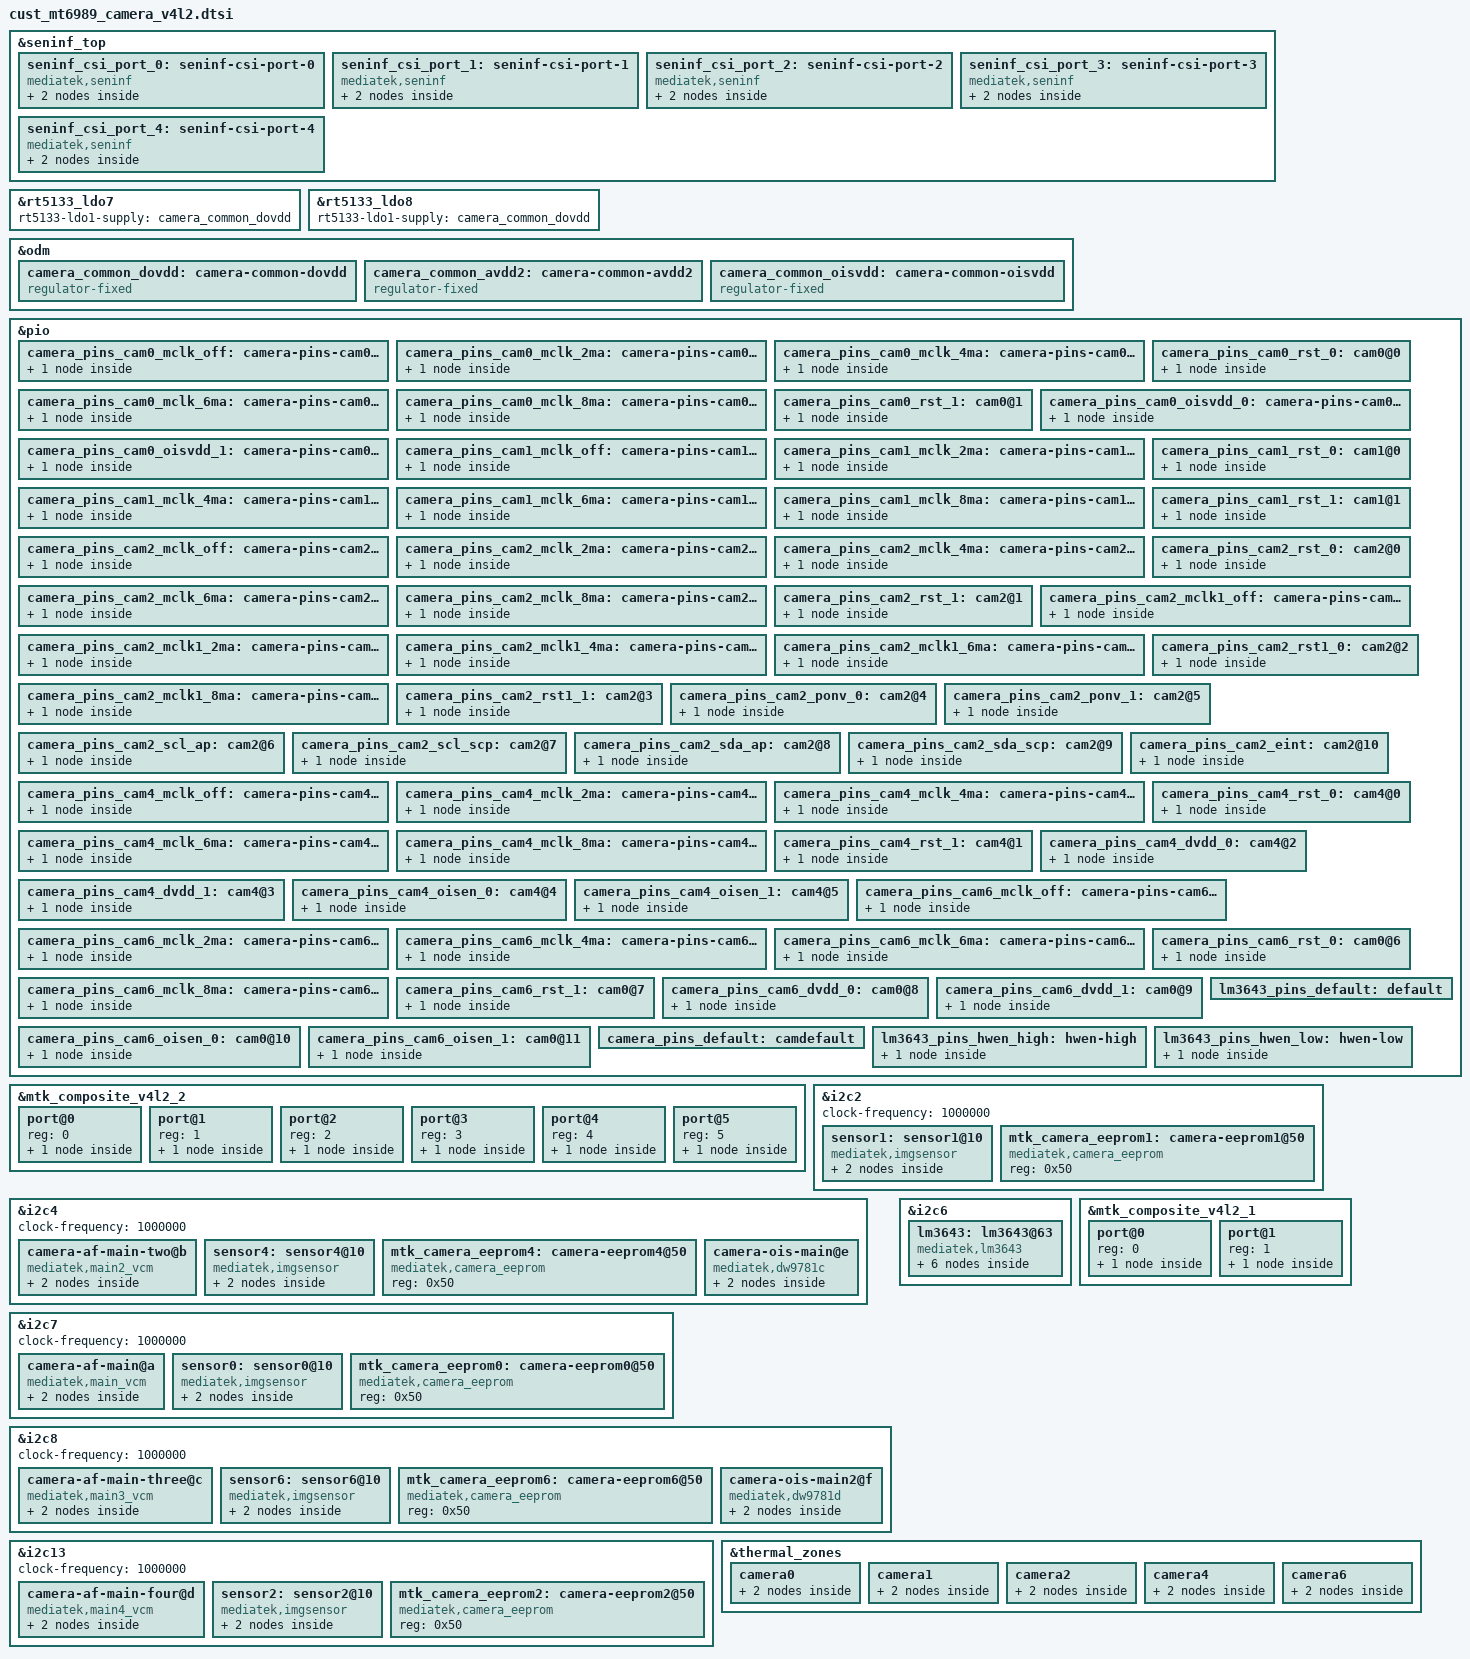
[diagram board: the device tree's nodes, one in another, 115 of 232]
// SPDX-License-Identifier: GPL-2.0
/* Copyright (c) 2023 MediaTek Inc. */
#include <dt-bindings/clock/mt6989-clk.h>

&seninf_top {
		seninf_csi_port_0: seninf-csi-port-0 {
			compatible = "mediatek,seninf";
			csi-port = "0";

			nvmem-cells = <&csi_efuse0>;
			nvmem-cell-names = "rg_csi";

			port {
				seninf_csi_port_0_in: endpoint {
					remote-endpoint = <&sensor1_out>;
				};
			};
		};

		seninf_csi_port_1: seninf-csi-port-1 {
			compatible = "mediatek,seninf";
			csi-port = "1";

			nvmem-cells = <&csi_efuse1>;
			nvmem-cell-names = "rg_csi";

			port {
				seninf_csi_port_1_in: endpoint {
					remote-endpoint = <&sensor6_out>;
				};
			};
		};

		seninf_csi_port_2: seninf-csi-port-2 {
			compatible = "mediatek,seninf";
			csi-port = "2";

			nvmem-cells = <&csi_efuse2>;
			nvmem-cell-names = "rg_csi";

			port {
				seninf_csi_port_2_in: endpoint {
					remote-endpoint = <&sensor4_out>;
				};
			};
		};
		seninf_csi_port_3: seninf-csi-port-3 {
			compatible = "mediatek,seninf";
			csi-port = "3";

			nvmem-cells = <&csi_efuse3>;
			nvmem-cell-names = "rg_csi";

			port {
				seninf_csi_port_3_in: endpoint {
					remote-endpoint = <&sensor0_out>;
				};
			};
		};
		seninf_csi_port_4: seninf-csi-port-4 {
			compatible = "mediatek,seninf";
			csi-port = "4";

			nvmem-cells = <&csi_efuse4>;
			nvmem-cell-names = "rg_csi";

			port {
				seninf_csi_port_4_in: endpoint {
					remote-endpoint = <&sensor2_out>;
				};
			};
		};
};

&rt5133_ldo7 {
	rt5133-ldo1-supply = <&camera_common_dovdd>;
};

&rt5133_ldo8 {
	rt5133-ldo1-supply = <&camera_common_dovdd>;
};

/* CAMERA GPIO fixed to regulator */
&odm {
	camera_common_dovdd: camera-common-dovdd {
		compatible = "regulator-fixed";
		regulator-name = "camera-common-dovdd";
		regulator-min-microvolt = <1800000>;
		regulator-max-microvolt = <1800000>;
		enable-active-high;
		gpio = <&pio 92 0x0>;
	};
	camera_common_avdd2: camera-common-avdd2 {
		compatible = "regulator-fixed";
		regulator-name = "camera-common-avdd2";
		regulator-min-microvolt = <1800000>;
		regulator-max-microvolt = <1800000>;
		enable-active-high;
		gpio = <&pio 93 0x0>;
	};
	camera_common_oisvdd: camera-common-oisvdd {
		compatible = "regulator-fixed";
		regulator-name = "camera-common-oisvdd";
		regulator-min-microvolt = <1800000>;
		regulator-max-microvolt = <1800000>;
		enable-active-high;
		gpio = <&pio 94 0x0>;
	};
};

/* CAMERA GPIO standardization */
&pio {
	camera_pins_cam0_mclk_off: camera-pins-cam0-mclk-off {
		pins-cmd-dat {
			pinmux = <PINMUX_GPIO116__FUNC_GPIO116>;
			drive-strength = <1>;
		};
	};
	camera_pins_cam0_mclk_2ma: camera-pins-cam0-mclk-2ma {
		pins-cmd-dat {
			pinmux = <PINMUX_GPIO116__FUNC_CMMCLK2>;
			drive-strength = <0>;
		};
	};
	camera_pins_cam0_mclk_4ma: camera-pins-cam0-mclk-4ma {
		pins-cmd-dat {
			pinmux = <PINMUX_GPIO116__FUNC_CMMCLK2>;
			drive-strength = <1>;
		};
	};
	camera_pins_cam0_mclk_6ma: camera-pins-cam0-mclk-6ma {
		pins-cmd-dat {
			pinmux = <PINMUX_GPIO116__FUNC_CMMCLK2>;
			drive-strength = <2>;
		};
	};
	camera_pins_cam0_mclk_8ma: camera-pins-cam0-mclk-8ma {
		pins-cmd-dat {
			pinmux = <PINMUX_GPIO116__FUNC_CMMCLK2>;
			drive-strength = <3>;
		};
	};
	camera_pins_cam0_rst_0: cam0@0 {
		pins-cmd-dat {
			pinmux = <PINMUX_GPIO118__FUNC_GPIO118>;
			slew-rate = <1>;
			output-low;
		};
	};
	camera_pins_cam0_rst_1: cam0@1 {
		pins-cmd-dat {
			pinmux = <PINMUX_GPIO118__FUNC_GPIO118>;
			slew-rate = <1>;
			output-high;
		};
	};
	camera_pins_cam0_oisvdd_0: camera-pins-cam0-oisvdd-0 {
		pins-cmd-dat {
			pinmux = <PINMUX_GPIO95__FUNC_GPIO95>;
			slew-rate = <1>;
			output-low;
		};
	};
	camera_pins_cam0_oisvdd_1: camera-pins-cam0-oisvdd-1 {
		pins-cmd-dat {
			pinmux = <PINMUX_GPIO95__FUNC_GPIO95>;
			slew-rate = <1>;
			output-high;
		};
	};
	camera_pins_cam1_mclk_off: camera-pins-cam1-mclk-off {
		pins-cmd-dat {
			pinmux = <PINMUX_GPIO106__FUNC_GPIO106>;
			drive-strength = <1>;
		};
	};
	camera_pins_cam1_mclk_2ma: camera-pins-cam1-mclk-2ma {
		pins-cmd-dat {
			pinmux = <PINMUX_GPIO106__FUNC_CMMCLK4>;
			drive-strength = <0>;
		};
	};
	camera_pins_cam1_mclk_4ma: camera-pins-cam1-mclk-4ma {
		pins-cmd-dat {
			pinmux = <PINMUX_GPIO106__FUNC_CMMCLK4>;
			drive-strength = <1>;
		};
	};
	camera_pins_cam1_mclk_6ma: camera-pins-cam1-mclk-6ma {
		pins-cmd-dat {
			pinmux = <PINMUX_GPIO106__FUNC_CMMCLK4>;
			drive-strength = <2>;
		};
	};
	camera_pins_cam1_mclk_8ma: camera-pins-cam1-mclk-8ma {
		pins-cmd-dat {
			pinmux = <PINMUX_GPIO106__FUNC_CMMCLK4>;
			drive-strength = <3>;
		};
	};
	camera_pins_cam1_rst_0: cam1@0 {
		pins-cmd-dat {
			pinmux = <PINMUX_GPIO114__FUNC_GPIO114>;
			slew-rate = <1>;
			output-low;
		};
	};
	camera_pins_cam1_rst_1: cam1@1 {
		pins-cmd-dat {
			pinmux = <PINMUX_GPIO114__FUNC_GPIO114>;
			slew-rate = <1>;
			output-high;
		};
	};
	camera_pins_cam2_mclk_off: camera-pins-cam2-mclk-off {
		pins-cmd-dat {
			pinmux = <PINMUX_GPIO117__FUNC_GPIO117>;
			drive-strength = <1>;
		};
	};
	camera_pins_cam2_mclk_2ma: camera-pins-cam2-mclk-2ma {
		pins-cmd-dat {
			pinmux = <PINMUX_GPIO117__FUNC_CMMCLK3>;
			drive-strength = <0>;
		};
	};
	camera_pins_cam2_mclk_4ma: camera-pins-cam2-mclk-4ma {
		pins-cmd-dat {
			pinmux = <PINMUX_GPIO117__FUNC_CMMCLK3>;
			drive-strength = <1>;
		};
	};
	camera_pins_cam2_mclk_6ma: camera-pins-cam2-mclk-6ma {
		pins-cmd-dat {
			pinmux = <PINMUX_GPIO117__FUNC_CMMCLK3>;
			drive-strength = <2>;
		};
	};
	camera_pins_cam2_mclk_8ma: camera-pins-cam2-mclk-8ma {
		pins-cmd-dat {
			pinmux = <PINMUX_GPIO117__FUNC_CMMCLK3>;
			drive-strength = <3>;
		};
	};
	camera_pins_cam2_rst_0: cam2@0 {
		pins-cmd-dat {
			pinmux = <PINMUX_GPIO119__FUNC_GPIO119>;
			slew-rate = <1>;
			output-low;
		};
	};
	camera_pins_cam2_rst_1: cam2@1 {
		pins-cmd-dat {
			pinmux = <PINMUX_GPIO119__FUNC_GPIO119>;
			slew-rate = <1>;
			output-high;
		};
	};
	camera_pins_cam2_mclk1_off: camera-pins-cam2-mclk1-off {
		pins-cmd-dat {
			pinmux = <PINMUX_GPIO124__FUNC_GPIO124>;
			drive-strength = <1>;
		};
	};
	camera_pins_cam2_mclk1_2ma: camera-pins-cam2-mclk1-2ma {
		pins-cmd-dat {
			pinmux = <PINMUX_GPIO124__FUNC_CMMCLK0>;
			drive-strength = <0>;
		};
	};
	camera_pins_cam2_mclk1_4ma: camera-pins-cam2-mclk1-4ma {
		pins-cmd-dat {
			pinmux = <PINMUX_GPIO124__FUNC_CMMCLK0>;
			drive-strength = <1>;
		};
	};
	camera_pins_cam2_mclk1_6ma: camera-pins-cam2-mclk1-6ma {
		pins-cmd-dat {
			pinmux = <PINMUX_GPIO124__FUNC_CMMCLK0>;
			drive-strength = <2>;
		};
	};
	camera_pins_cam2_mclk1_8ma: camera-pins-cam2-mclk1-8ma {
		pins-cmd-dat {
			pinmux = <PINMUX_GPIO124__FUNC_CMMCLK0>;
			drive-strength = <3>;
		};
	};
	camera_pins_cam2_rst1_0: cam2@2 {
		pins-cmd-dat {
			pinmux = <PINMUX_GPIO160__FUNC_GPIO160>;
			slew-rate = <1>;
			output-low;
		};
	};
	camera_pins_cam2_rst1_1: cam2@3 {
		pins-cmd-dat {
			pinmux = <PINMUX_GPIO160__FUNC_GPIO160>;
			slew-rate = <1>;
			output-high;
		};
	};
	camera_pins_cam2_ponv_0: cam2@4 {
		pins-cmd-dat {
			pinmux = <PINMUX_GPIO159__FUNC_GPIO159>;
			slew-rate = <1>;
			output-low;
		};
	};
	camera_pins_cam2_ponv_1: cam2@5 {
		pins-cmd-dat {
			pinmux = <PINMUX_GPIO159__FUNC_GPIO159>;
			slew-rate = <1>;
			output-high;
		};
	};
	camera_pins_cam2_scl_ap: cam2@6 {
		pins-cmd-dat {
			pinmux = <PINMUX_GPIO104__FUNC_SCL13>;
		};
	};
	camera_pins_cam2_scl_scp: cam2@7 {
		pins-cmd-dat {
			pinmux = <PINMUX_GPIO104__FUNC_SCP_SCL3>;
		};
	};
	camera_pins_cam2_sda_ap: cam2@8 {
		pins-cmd-dat {
			pinmux = <PINMUX_GPIO105__FUNC_SDA13>;
		};
	};
	camera_pins_cam2_sda_scp: cam2@9 {
		pins-cmd-dat {
			pinmux = <PINMUX_GPIO105__FUNC_SCP_SDA3>;
		};
	};
	camera_pins_cam2_eint: cam2@10 {
		pins-cmd-dat {
			pinmux = <PINMUX_GPIO109__FUNC_GPIO109>;
			bias-pull-up;
			input-enable;
		};
	};
	camera_pins_cam4_mclk_off: camera-pins-cam4-mclk-off {
		pins-cmd-dat {
			pinmux = <PINMUX_GPIO125__FUNC_GPIO125>;
			drive-strength = <1>;
		};
	};
	camera_pins_cam4_mclk_2ma: camera-pins-cam4-mclk-2ma {
		pins-cmd-dat {
			pinmux = <PINMUX_GPIO125__FUNC_CMMCLK1>;
			drive-strength = <0>;
		};
	};
	camera_pins_cam4_mclk_4ma: camera-pins-cam4-mclk-4ma {
		pins-cmd-dat {
			pinmux = <PINMUX_GPIO125__FUNC_CMMCLK1>;
			drive-strength = <1>;
		};
	};
	camera_pins_cam4_mclk_6ma: camera-pins-cam4-mclk-6ma {
		pins-cmd-dat {
			pinmux = <PINMUX_GPIO125__FUNC_CMMCLK1>;
			drive-strength = <2>;
		};
	};
	camera_pins_cam4_mclk_8ma: camera-pins-cam4-mclk-8ma {
		pins-cmd-dat {
			pinmux = <PINMUX_GPIO125__FUNC_CMMCLK1>;
			drive-strength = <3>;
		};
	};
	camera_pins_cam4_rst_0: cam4@0 {
		pins-cmd-dat {
			pinmux = <PINMUX_GPIO127__FUNC_GPIO127>;
			slew-rate = <1>;
			output-low;
		};
	};
	camera_pins_cam4_rst_1: cam4@1 {
		pins-cmd-dat {
			pinmux = <PINMUX_GPIO127__FUNC_GPIO127>;
			slew-rate = <1>;
			output-high;
		};
	};
	camera_pins_cam4_dvdd_0: cam4@2 {
		pins-cmd-dat {
			pinmux = <PINMUX_GPIO108__FUNC_GPIO108>;
			slew-rate = <1>;
			output-low;
		};
	};
	camera_pins_cam4_dvdd_1: cam4@3 {
		pins-cmd-dat {
			pinmux = <PINMUX_GPIO108__FUNC_GPIO108>;
			slew-rate = <1>;
			output-high;
		};
	};
	camera_pins_cam4_oisen_0: cam4@4 {
		pins-cmd-dat {
			pinmux = <PINMUX_GPIO189__FUNC_GPIO189>;
			slew-rate = <1>;
			output-low;
		};
	};
	camera_pins_cam4_oisen_1: cam4@5 {
		pins-cmd-dat {
			pinmux = <PINMUX_GPIO189__FUNC_GPIO189>;
			slew-rate = <1>;
			output-high;
		};
	};
	camera_pins_cam6_mclk_off: camera-pins-cam6-mclk-off {
		pins-cmd-dat {
			pinmux = <PINMUX_GPIO107__FUNC_GPIO107>;
			drive-strength = <1>;
		};
	};
	camera_pins_cam6_mclk_2ma: camera-pins-cam6-mclk-2ma {
		pins-cmd-dat {
			pinmux = <PINMUX_GPIO107__FUNC_CMMCLK5>;
			drive-strength = <0>;
		};
	};
	camera_pins_cam6_mclk_4ma: camera-pins-cam6-mclk-4ma {
		pins-cmd-dat {
			pinmux = <PINMUX_GPIO107__FUNC_CMMCLK5>;
			drive-strength = <1>;
		};
	};
	camera_pins_cam6_mclk_6ma: camera-pins-cam6-mclk-6ma {
		pins-cmd-dat {
			pinmux = <PINMUX_GPIO107__FUNC_CMMCLK5>;
			drive-strength = <2>;
		};
	};
	camera_pins_cam6_mclk_8ma: camera-pins-cam6-mclk-8ma {
		pins-cmd-dat {
			pinmux = <PINMUX_GPIO107__FUNC_CMMCLK5>;
			drive-strength = <3>;
		};
	};
	camera_pins_cam6_rst_0: cam0@6 {
		pins-cmd-dat {
			pinmux = <PINMUX_GPIO110__FUNC_GPIO110>;
			slew-rate = <1>;
			output-low;
		};
	};
	camera_pins_cam6_rst_1: cam0@7 {
		pins-cmd-dat {
			pinmux = <PINMUX_GPIO110__FUNC_GPIO110>;
			slew-rate = <1>;
			output-high;
		};
	};
	camera_pins_cam6_dvdd_0: cam0@8 {
		pins-cmd-dat {
			pinmux = <PINMUX_GPIO126__FUNC_GPIO126>;
			slew-rate = <1>;
			output-low;
		};
	};
	camera_pins_cam6_dvdd_1: cam0@9 {
		pins-cmd-dat {
			pinmux = <PINMUX_GPIO126__FUNC_GPIO126>;
			slew-rate = <1>;
			output-high;
		};
	};
	camera_pins_cam6_oisen_0: cam0@10 {
		pins-cmd-dat {
			pinmux = <PINMUX_GPIO223__FUNC_GPIO223>;
			slew-rate = <1>;
			output-low;
		};
	};
	camera_pins_cam6_oisen_1: cam0@11 {
		pins-cmd-dat {
			pinmux = <PINMUX_GPIO223__FUNC_GPIO223>;
			slew-rate = <1>;
			output-high;
		};
	};
	camera_pins_default: camdefault {
	};
};
/* CAMERA GPIO end */

&mtk_composite_v4l2_2 {
	#address-cells = <1>;
	#size-cells = <0>;
	port@0 {
		reg = <0>;
		main_af_endpoint: endpoint {
			remote-endpoint = <&main_af>;
		};
	};
	port@1 {
		reg = <1>;
		main_af_cam1_endpoint: endpoint {
			remote-endpoint = <&main_af_cam1>;
		};
	};
	port@2 {
		reg = <2>;
		main_af_cam2_endpoint: endpoint {
			remote-endpoint = <&main_af_cam2>;
		};
	};
	port@3 {
		reg = <3>;
		main_af_cam3_endpoint: endpoint {
			remote-endpoint = <&main_af_cam3>;
		};
	};
	port@4 {
		reg = <4>;
		main_ois_cam1_endpoint: endpoint {
			remote-endpoint = <&main_ois_cam1>;
		};
	};
	port@5 {
		reg = <5>;
		main_ois_cam2_endpoint: endpoint {
			remote-endpoint = <&main_ois_cam2>;
		};
	};
};

&i2c2 {
	status = "okay";
	clock-frequency = <1000000>;

	sensor1: sensor1@10 {
		compatible = "mediatek,imgsensor";
		sensor-names = "s5k3p9sp_mipi_raw";
		reg = <0x10>;

		#thermal-sensor-cells = <0>;

		pinctrl-names = "mclk_off",
				"mclk_2mA",
				"mclk_4mA",
				"mclk_6mA",
				"mclk_8mA",
				"rst_low",
				"rst_high";
		pinctrl-0 = <&camera_pins_cam1_mclk_off>;
		pinctrl-1 = <&camera_pins_cam1_mclk_2ma>;
		pinctrl-2 = <&camera_pins_cam1_mclk_4ma>;
		pinctrl-3 = <&camera_pins_cam1_mclk_6ma>;
		pinctrl-4 = <&camera_pins_cam1_mclk_8ma>;
		pinctrl-5 = <&camera_pins_cam1_rst_0>;
		pinctrl-6 = <&camera_pins_cam1_rst_1>;

		avdd-supply = <&rt5133_ldo3>;
		dvdd1-supply = <&rt5133_gpio3>;
		dovdd-supply = <&camera_common_dovdd>;

		clocks = <&topckgen_clk CLK_TOP_UNIVPLL2_192M_D32>,
			<&topckgen_clk CLK_TOP_UNIVPLL2_192M_D16>,
			<&topckgen_clk CLK_TOP_F26M_CK_D2>,
			<&topckgen_clk CLK_TOP_UNIVPLL2_192M_D10>,
			<&topckgen_clk CLK_TOP_UNIVPLL2_192M_D8>,
			<&topckgen_clk CLK_TOP_UNIVPLL2_D6_D16>,
			<&topckgen_clk CLK_TOP_UNIVPLL2_D6_D8>,
			<&topckgen_clk CLK_TOP_CAMTG4_SEL>;
		clock-names = "6", "12", "13", "19.2", "24", "26", "52", "mclk";

		status = "okay";
		port {
			sensor1_out: endpoint {
				remote-endpoint = <&seninf_csi_port_0_in>;
			};
		};
	};

	mtk_camera_eeprom1:camera-eeprom1@50 {
		compatible = "mediatek,camera_eeprom";
		reg = <0x50>;
		status = "okay";
	};
};

&i2c4 {
	status = "okay";
	clock-frequency = <1000000>;

	camera-af-main-two@b {
		compatible = "mediatek,main2_vcm";
		reg = <0x0b>;
		vin-supply = <&rt5133_ldo2>;
		port {
			main_af_cam1: endpoint {
				remote-endpoint = <&main_af_cam1_endpoint>;
			};
		};
	};

	sensor4: sensor4@10 {
		compatible = "mediatek,imgsensor";
		sensor-names = "imx758_mipi_raw";
		reg = <0x10>;

		#thermal-sensor-cells = <0>;

		pinctrl-names = "mclk_off",
				"mclk_2mA",
				"mclk_4mA",
				"mclk_6mA",
				"mclk_8mA",
				"rst_low",
				"rst_high",
				"dvdd_off",
				"dvdd_on",
				"oisen_off",
				"oisen_on";
		pinctrl-0 = <&camera_pins_cam4_mclk_off>;
		pinctrl-1 = <&camera_pins_cam4_mclk_2ma>;
		pinctrl-2 = <&camera_pins_cam4_mclk_4ma>;
		pinctrl-3 = <&camera_pins_cam4_mclk_6ma>;
		pinctrl-4 = <&camera_pins_cam4_mclk_8ma>;
		pinctrl-5 = <&camera_pins_cam4_rst_0>;
		pinctrl-6 = <&camera_pins_cam4_rst_1>;
		pinctrl-7 = <&camera_pins_cam4_dvdd_0>;
		pinctrl-8 = <&camera_pins_cam4_dvdd_1>;
		pinctrl-9 = <&camera_pins_cam4_oisen_0>;
		pinctrl-10 = <&camera_pins_cam4_oisen_1>;

		avdd-supply = <&rt5133_ldo3>;
		afvdd-supply = <&rt5133_ldo2>;
		dovdd-supply = <&camera_common_dovdd>;
		oisvdd-supply = <&rt5133_ldo1>;

		clocks = <&topckgen_clk CLK_TOP_UNIVPLL2_192M_D32>,
			<&topckgen_clk CLK_TOP_UNIVPLL2_192M_D16>,
			<&topckgen_clk CLK_TOP_F26M_CK_D2>,
			<&topckgen_clk CLK_TOP_UNIVPLL2_192M_D10>,
			<&topckgen_clk CLK_TOP_UNIVPLL2_192M_D8>,
			<&topckgen_clk CLK_TOP_UNIVPLL2_D6_D16>,
			<&topckgen_clk CLK_TOP_UNIVPLL2_D6_D8>,
			<&topckgen_clk CLK_TOP_CAMTG1_SEL>;
		clock-names = "6", "12", "13", "19.2", "24", "26", "52", "mclk";

		status = "okay";
		port {
			sensor4_out: endpoint {
				remote-endpoint = <&seninf_csi_port_2_in>;
			};
		};
	};

	mtk_camera_eeprom4:camera-eeprom4@50 {
		compatible = "mediatek,camera_eeprom";
		reg = <0x50>;
		status = "okay";
	};

	/* ois */
	camera-ois-main@e {
		compatible = "mediatek,dw9781c";
		reg = <0x0e>;
		vdd-supply = <&rt5133_ldo1>;
		rst-supply = <&camera_common_dovdd>;
		port {
			main_ois_cam1: endpoint {
				remote-endpoint = <&main_ois_cam1_endpoint>;
			};
		};
	};
};

&i2c7 {
	status = "okay";
	clock-frequency = <1000000>;

	camera-af-main@a {
		compatible = "mediatek,main_vcm";
		reg = <0x0a>;
		vin-supply = <&rt5133_gpio1>;
		port {
			main_af: endpoint {
				remote-endpoint = <&main_af_endpoint>;
			};
		};
	};

	sensor0: sensor0@10 {
		compatible = "mediatek,imgsensor";
		sensor-names = "ov48b_mipi_raw",
				"imx989_mipi_raw",
				"imx966_mipi_raw",
				"s5khp3sp_mipi_raw",
				"s5kgn9sp_mipi_raw";
		reg = <0x10>;

		#thermal-sensor-cells = <0>;

		pinctrl-names = "mclk_off",
				"mclk_2mA",
				"mclk_4mA",
				"mclk_6mA",
				"mclk_8mA",
				"rst_low",
				"rst_high",
				"oisvdd_off",
				"oisvdd_on";
		pinctrl-0 = <&camera_pins_cam0_mclk_off>;
		pinctrl-1 = <&camera_pins_cam0_mclk_2ma>;
		pinctrl-2 = <&camera_pins_cam0_mclk_4ma>;
		pinctrl-3 = <&camera_pins_cam0_mclk_6ma>;
		pinctrl-4 = <&camera_pins_cam0_mclk_8ma>;
		pinctrl-5 = <&camera_pins_cam0_rst_0>;
		pinctrl-6 = <&camera_pins_cam0_rst_1>;
		pinctrl-7 = <&camera_pins_cam0_oisvdd_0>;
		pinctrl-8 = <&camera_pins_cam0_oisvdd_1>;

		avdd-supply = <&rt5133_ldo5>;
		avdd2-supply = <&camera_common_avdd2>;
		dvdd-supply = <&rt5133_ldo8>;
		afvdd1-supply = <&rt5133_gpio1>;
		dovdd-supply = <&camera_common_dovdd>;

		clocks = <&topckgen_clk CLK_TOP_UNIVPLL2_192M_D32>,
			<&topckgen_clk CLK_TOP_UNIVPLL2_192M_D16>,
			<&topckgen_clk CLK_TOP_F26M_CK_D2>,
			<&topckgen_clk CLK_TOP_UNIVPLL2_192M_D10>,
			<&topckgen_clk CLK_TOP_UNIVPLL2_192M_D8>,
			<&topckgen_clk CLK_TOP_UNIVPLL2_D6_D16>,
			<&topckgen_clk CLK_TOP_UNIVPLL2_D6_D8>,
			<&topckgen_clk CLK_TOP_CAMTG2_SEL>;
		clock-names = "6", "12", "13", "19.2", "24", "26", "52", "mclk";

		status = "okay";
		port {
			sensor0_out: endpoint {
				remote-endpoint = <&seninf_csi_port_3_in>;
			};
		};
	};

	mtk_camera_eeprom0:camera-eeprom0@50 {
		compatible = "mediatek,camera_eeprom";
		reg = <0x50>;
		status = "okay";
	};
};

&i2c8 {
	status = "okay";
	clock-frequency = <1000000>;

	camera-af-main-three@c {
		compatible = "mediatek,main3_vcm";
		reg = <0x0c>;
		vin-supply = <&rt5133_gpio1>;
		port {
			main_af_cam2: endpoint {
				remote-endpoint = <&main_af_cam2_endpoint>;
			};
		};
	};

	sensor6: sensor6@10 {
		compatible = "mediatek,imgsensor";
		sensor-names = "ov64b_mipi_raw";
		reg = <0x10>;

		#thermal-sensor-cells = <0>;

		pinctrl-names = "mclk_off",
				"mclk_2mA",
				"mclk_4mA",
				"mclk_6mA",
				"mclk_8mA",
				"rst_low",
				"rst_high",
				"dvdd_off",
				"dvdd_on",
				"oisen_off",
				"oisen_on";
		pinctrl-0 = <&camera_pins_cam6_mclk_off>;
		pinctrl-1 = <&camera_pins_cam6_mclk_2ma>;
		pinctrl-2 = <&camera_pins_cam6_mclk_4ma>;
		pinctrl-3 = <&camera_pins_cam6_mclk_6ma>;
		pinctrl-4 = <&camera_pins_cam6_mclk_8ma>;
		pinctrl-5 = <&camera_pins_cam6_rst_0>;
		pinctrl-6 = <&camera_pins_cam6_rst_1>;
		pinctrl-7 = <&camera_pins_cam6_dvdd_0>;
		pinctrl-8 = <&camera_pins_cam6_dvdd_1>;
		pinctrl-9 = <&camera_pins_cam6_oisen_0>;
		pinctrl-10 = <&camera_pins_cam6_oisen_1>;

		avdd-supply = <&rt5133_ldo4>;
		afvdd1-supply = <&rt5133_gpio1>;
		dovdd-supply = <&camera_common_dovdd>;
		oisvdd-supply = <&camera_common_oisvdd>;

		clocks = <&topckgen_clk CLK_TOP_UNIVPLL2_192M_D32>,
			<&topckgen_clk CLK_TOP_UNIVPLL2_192M_D16>,
			<&topckgen_clk CLK_TOP_F26M_CK_D2>,
			<&topckgen_clk CLK_TOP_UNIVPLL2_192M_D10>,
			<&topckgen_clk CLK_TOP_UNIVPLL2_192M_D8>,
			<&topckgen_clk CLK_TOP_UNIVPLL2_D6_D16>,
			<&topckgen_clk CLK_TOP_UNIVPLL2_D6_D8>,
			<&topckgen_clk CLK_TOP_CAMTG5_SEL>;
		clock-names = "6", "12", "13", "19.2", "24", "26", "52", "mclk";

		status = "okay";
		port {
			sensor6_out: endpoint {
				remote-endpoint = <&seninf_csi_port_1_in>;
			};
		};
	};

	mtk_camera_eeprom6:camera-eeprom6@50 {
		compatible = "mediatek,camera_eeprom";
		reg = <0x50>;
		status = "okay";
	};

	/* ois */
	camera-ois-main2@f {
		compatible = "mediatek,dw9781d";
		reg = <0x0f>;
		vdd-supply = <&camera_common_oisvdd>;
		rst-supply = <&camera_common_dovdd>;
		port {
			main_ois_cam2: endpoint {
				remote-endpoint = <&main_ois_cam2_endpoint>;
			};
		};
	};
};

&i2c13 {
	status = "okay";
	clock-frequency = <1000000>;

	camera-af-main-four@d {
		compatible = "mediatek,main4_vcm";
		reg = <0x0d>;
		vin-supply = <&rt5133_ldo2>;
		port {
			main_af_cam3: endpoint {
				remote-endpoint = <&main_af_cam3_endpoint>;
			};
		};
	};

	sensor2: sensor2@10 {
		compatible = "mediatek,imgsensor";
		sensor-names = "imx598_mipi_raw",
				"imx709_mipi_raw",
				"imx866_mipi_raw";
		reg = <0x10>;
		reindex-match = "imx709_mipi_raw",
				"imx866_mipi_raw";
		reindex-to = <0>;

		cust-aov-csi-clk = <312>;

		#thermal-sensor-cells = <0>;

		pinctrl-names = "mclk_off",
				"mclk_2mA",
				"mclk_4mA",
				"mclk_6mA",
				"mclk_8mA",
				"rst_low",
				"rst_high",
				"mclk1_off",
				"mclk1_2mA",
				"mclk1_4mA",
				"mclk1_6mA",
				"mclk1_8mA",
				"rst1_low",
				"rst1_high",
				"ponv_low",
				"ponv_high",
				"scl_ap",
				"scl_scp",
				"sda_ap",
				"sda_scp",
				"eint";
		pinctrl-0 = <&camera_pins_cam2_mclk_off>;
		pinctrl-1 = <&camera_pins_cam2_mclk_2ma>;
		pinctrl-2 = <&camera_pins_cam2_mclk_4ma>;
		pinctrl-3 = <&camera_pins_cam2_mclk_6ma>;
		pinctrl-4 = <&camera_pins_cam2_mclk_8ma>;
		pinctrl-5 = <&camera_pins_cam2_rst_0>;
		pinctrl-6 = <&camera_pins_cam2_rst_1>;
		pinctrl-7 = <&camera_pins_cam2_mclk1_off>;
		pinctrl-8 = <&camera_pins_cam2_mclk1_2ma>;
		pinctrl-9 = <&camera_pins_cam2_mclk1_4ma>;
		pinctrl-10 = <&camera_pins_cam2_mclk1_6ma>;
		pinctrl-11 = <&camera_pins_cam2_mclk1_8ma>;
		pinctrl-12 = <&camera_pins_cam2_rst1_0>;
		pinctrl-13 = <&camera_pins_cam2_rst1_1>;
		pinctrl-14 = <&camera_pins_cam2_ponv_0>;
		pinctrl-15 = <&camera_pins_cam2_ponv_1>;
		pinctrl-16 = <&camera_pins_cam2_scl_ap>;
		pinctrl-17 = <&camera_pins_cam2_scl_scp>;
		pinctrl-18 = <&camera_pins_cam2_sda_ap>;
		pinctrl-19 = <&camera_pins_cam2_sda_scp>;
		pinctrl-20 = <&camera_pins_cam2_eint>;

		avdd-supply = <&rt5133_ldo6>; // AVDD for imx598/imx709
		avdd3-supply = <&camera_common_avdd2>; // AVDD2 for imx866
		avdd4-supply = <&rt5133_gpio2>; // AVDD2 for imx598
		dvdd-supply = <&rt5133_ldo7>; // DVDD for imx598
		dvdd2-supply = <&rt5133_ldo8>; // DVDD for imx709
		afvdd-supply = <&rt5133_ldo2>;
		dovdd-supply = <&camera_common_dovdd>;

		clocks = <&topckgen_clk CLK_TOP_UNIVPLL2_192M_D32>,
			<&topckgen_clk CLK_TOP_UNIVPLL2_192M_D16>,
			<&topckgen_clk CLK_TOP_F26M_CK_D2>,
			<&topckgen_clk CLK_TOP_UNIVPLL2_192M_D10>,
			<&topckgen_clk CLK_TOP_UNIVPLL2_192M_D8>,
			<&topckgen_clk CLK_TOP_UNIVPLL2_D6_D16>,
			<&topckgen_clk CLK_TOP_UNIVPLL2_D6_D8>,
			<&topckgen_clk CLK_TOP_CAMTG3_SEL>,
			<&topckgen_clk CLK_TOP_UNIVPLL_192M_D32>,
			<&topckgen_clk CLK_TOP_UNIVPLL_192M_D16>,
			<&topckgen_clk CLK_TOP_F26M_CK_D2>,
			<&topckgen_clk CLK_TOP_UNIVPLL_192M_D10>,
			<&topckgen_clk CLK_TOP_UNIVPLL_192M_D8>,
			<&topckgen_clk CLK_TOP_UNIVPLL_D6_D16>,
			<&topckgen_clk CLK_TOP_OSC_D20>,
			<&topckgen_clk CLK_TOP_UNIVPLL_D6_D8>,
			<&vlp_cksys_clk CLK_VLP_CK_CAMTG0_SEL>;
		clock-names = "6", "12", "13", "19.2", "24", "26", "52", "mclk",
			      "clk1_6", "clk1_12", "clk1_13", "clk1_19.2",
			      "clk1_24", "clk1_26", "clk1_26_ulposc", "clk1_52", "clk1_mclk1";

		status = "okay";
		port {
			sensor2_out: endpoint {
				remote-endpoint = <&seninf_csi_port_4_in>;
			};
		};
	};

	mtk_camera_eeprom2:camera-eeprom2@50 {
		compatible = "mediatek,camera_eeprom";
		reg = <0x50>;
		status = "okay";
	};
};

&i2c6 {
	#address-cells = <1>;
	#size-cells = <0>;
	lm3643:lm3643@63 {
		compatible = "mediatek,lm3643";
		#address-cells = <1>;
		#size-cells = <0>;
		reg = <0x63>;
		#cooling-cells = <2>;
		pinctrl-names = "default", "hwen-high", "hwen-low";
		pinctrl-0 = <&lm3643_pins_default>;
		pinctrl-1 = <&lm3643_pins_hwen_high>;
		pinctrl-2 = <&lm3643_pins_hwen_low>;
		status = "okay";
		flash@0{
			reg = <0>;
			type = <0>;
			ct = <0>;
			part = <0>;
			port {
				fl_core_0: endpoint {
					remote-endpoint = <&flashlight_0>;
				};
			};
		};
		flash@1{
			reg = <1>;
			type = <0>;
			ct = <1>;
			part = <0>;
			port {
				fl_core_1: endpoint {
					remote-endpoint = <&flashlight_1>;
				};
			};
		};
	};
};

&pio {
	lm3643_pins_default: default {
	};

	lm3643_pins_hwen_high: hwen-high {
		pins-cmd-dat {
			pinmux = <PINMUX_GPIO7__FUNC_GPIO7>;
			slew-rate = <1>;
			output-high;
		};
	};

	lm3643_pins_hwen_low: hwen-low {
		pins-cmd-dat {
			pinmux = <PINMUX_GPIO7__FUNC_GPIO7>;
			slew-rate = <1>;
			output-low;
		};
	};
};

&mtk_composite_v4l2_1 {
	#address-cells = <1>;
	#size-cells = <0>;
	port@0 {
		reg = <0>;
		flashlight_0: endpoint {
			remote-endpoint = <&fl_core_0>;
		};
	};
	port@1 {
		reg = <1>;
		flashlight_1: endpoint {
			remote-endpoint = <&fl_core_1>;
		};
	};
};


&thermal_zones {
	camera0: camera0 {
		polling-delay = <0>; /* milliseconds */
		polling-delay-passive = <0>; /* milliseconds */
		thermal-sensors = <&sensor0>;
		trips {
			camera0_crit: camera0-crit {
				temperature = <120000>;
				hysteresis = <2000>;
				type = "passive";
			};
		};
	};
	camera1: camera1 {
		polling-delay = <0>; /* milliseconds */
		polling-delay-passive = <0>; /* milliseconds */
		thermal-sensors = <&sensor1>;
		trips {
			camera1_crit: camera1-crit {
				temperature = <120000>;
				hysteresis = <2000>;
				type = "passive";
			};
		};
	};
	camera2: camera2 {
		polling-delay = <0>; /* milliseconds */
		polling-delay-passive = <0>; /* milliseconds */
		thermal-sensors = <&sensor2>;
		trips {
			camera2_crit: camera2-crit {
				temperature = <120000>;
				hysteresis = <2000>;
				type = "passive";
			};
		};
	};
	camera4: camera4 {
		polling-delay = <0>; /* milliseconds */
		polling-delay-passive = <0>; /* milliseconds */
		thermal-sensors = <&sensor4>;
		trips {
			camera4_crit: camera4-crit {
				temperature = <120000>;
				hysteresis = <2000>;
				type = "passive";
			};
		};
	};
	camera6: camera6 {
		polling-delay = <0>; /* milliseconds */
		polling-delay-passive = <0>; /* milliseconds */
		thermal-sensors = <&sensor6>;
		trips {
			camera6_crit: camera6-crit {
				temperature = <120000>;
				hysteresis = <2000>;
				type = "passive";
			};
		};
	};
};
